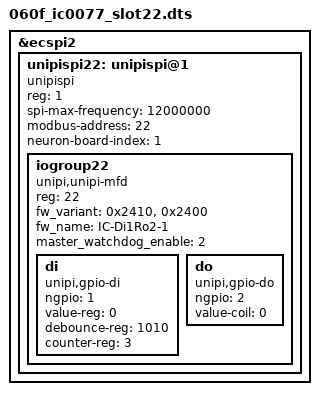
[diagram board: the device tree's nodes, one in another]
/dts-v1/;


/plugin/;

/ {
	fragment@1 {
		
		target = <&ecspi2>;
		__overlay__ {
			status = "okay";
			#address-cells = <1>;
			#size-cells = <0>;

			unipispi22: unipispi@1 {
				compatible = "unipispi";
				reg = <1>;
				status = "okay";
				spi-max-frequency = <12000000>;
				modbus-address = <22>;
				neuron-board-index = <1>;
			};
		};

	};

	fragment@2 {
		target = <&unipispi22>;
		__overlay__ {
			#address-cells = <1>;
			#size-cells = <0>;

			iogroup22 {
				reg = <22>;
				compatible = "unipi,unipi-mfd", "iogroup";
				fw_variant = <0x2410>,  <0x2400>;
				fw_name = "IC-Di1Ro2-1";
				master_watchdog_enable = <2>;
				di {
					compatible = "unipi,gpio-di";
					ngpio = <1>;
					value-reg = <0>;
					debounce-reg = <1010>;
					counter-reg = <3>;
				};
				do {
					compatible = "unipi,gpio-do";
					ngpio = <2>;
					value-coil = <0>;
				};
			};
		};
	};
};
